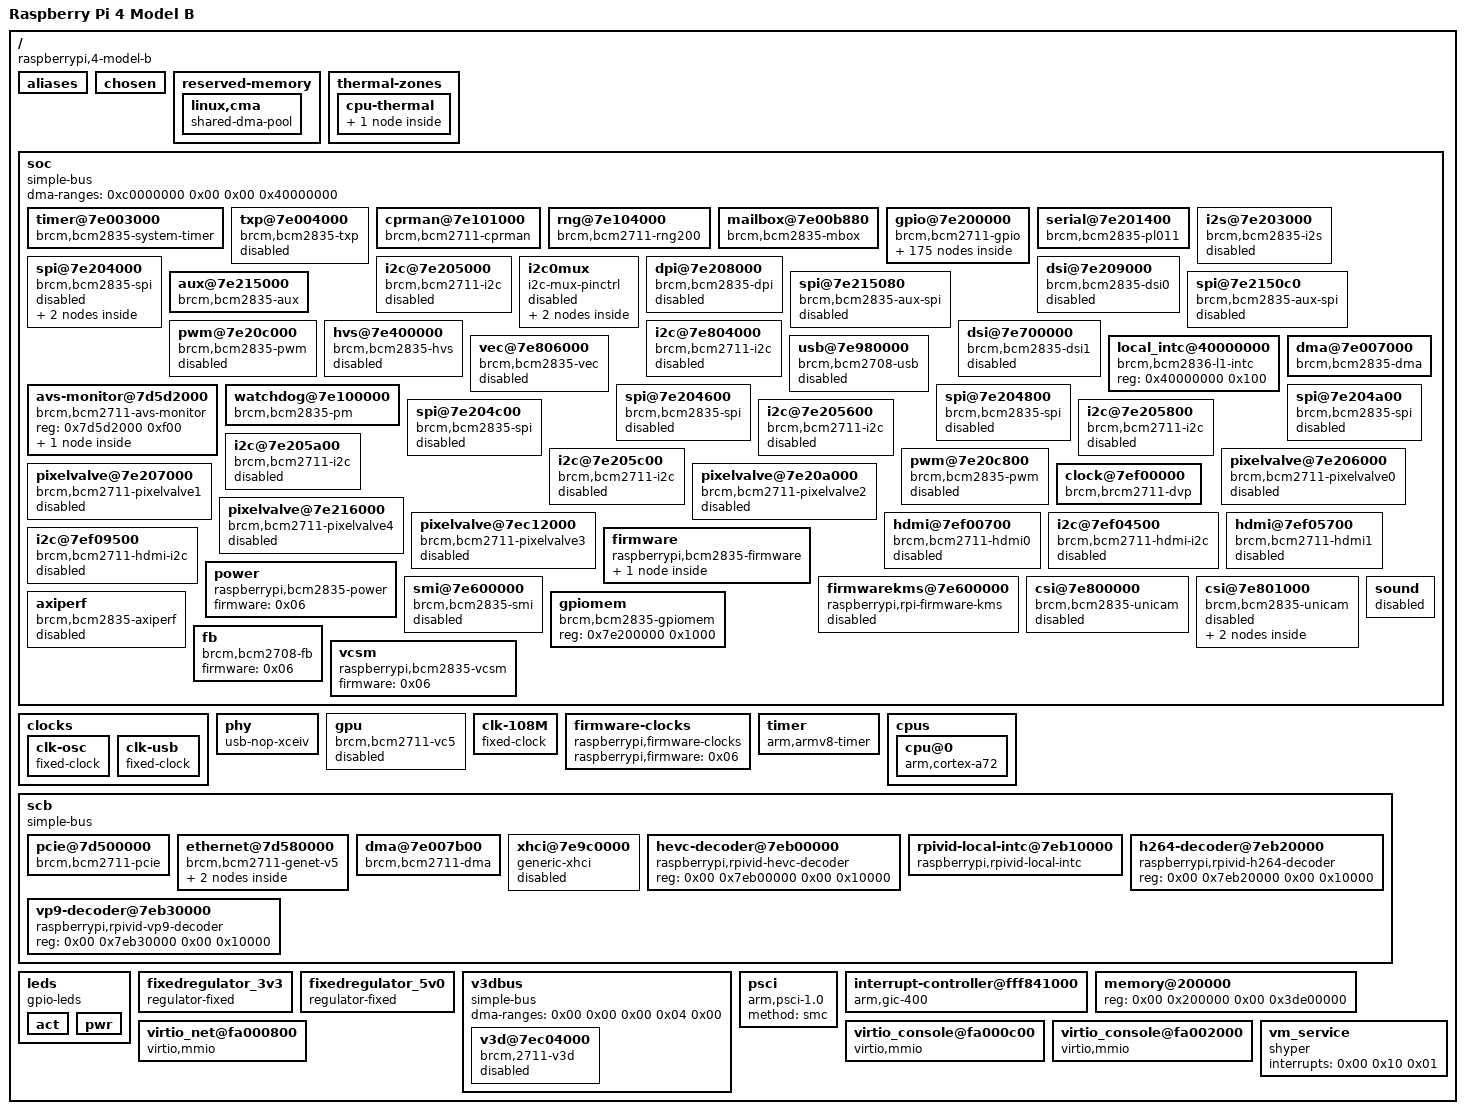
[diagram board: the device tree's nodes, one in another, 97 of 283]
/dts-v1/;

/memreserve/	0x0000000000000000 0x0000000000080000;
/ {
	compatible = "raspberrypi,4-model-b\0brcm,bcm2711";
	model = "Raspberry Pi 4 Model B";
	#address-cells = <0x02>;
	#size-cells = <0x02>;
	interrupt-parent = <0x01>;

	aliases {
		serial0 = "/soc/serial@7e201400";
		ethernet0 = "/scb/ethernet@7d580000";
		audio = "/soc/mailbox@7e00b840/bcm2835_audio";
		aux = "/soc/aux@7e215000";
		sound = "/soc/sound";
		soc = "/soc";
		dma = "/soc/dma@7e007000";
		watchdog = "/soc/watchdog@7e100000";
		random = "/soc/rng@7e104000";
		mailbox = "/soc/mailbox@7e00b880";
		gpio = "/soc/gpio@7e200000";
		i2s = "/soc/i2s@7e203000";
		i2c0 = "/soc/i2c0mux/i2c@0";
		i2c1 = "/soc/i2c@7e804000";
		i2c10 = "/soc/i2c0mux/i2c@1";
		spi0 = "/soc/spi@7e204000";
		spi1 = "/soc/spi@7e215080";
		spi2 = "/soc/spi@7e2150c0";
		usb = "/soc/usb@7e980000";
		leds = "/leds";
		fb = "/soc/fb";
		thermal = "/soc/avs-monitor@7d5d2000/thermal";
		axiperf = "/soc/axiperf";
		i2c3 = "/soc/i2c@7e205600";
		i2c4 = "/soc/i2c@7e205800";
		i2c5 = "/soc/i2c@7e205a00";
		i2c6 = "/soc/i2c@7e205c00";
		pcie0 = "/scb/pcie@7d500000";
	};

	chosen {
		// stdout-path = "serial0:115200n8";
		bootargs = "coherent_pool=1M snd_bcm2835.enable_compat_alsa=0 snd_bcm2835.enable_hdmi=1 snd_bcm2835.enable_headphones=1 console=ttyAMA0,115200n8 root=/dev/sda1 rootfstype=ext4 rw audit=0 rootwait default_hugepagesz=32M hugepagesz=32M hugepages=4";
		// bootargs = "console=ttyAMA0,115200n8 rdinit=/sbin/init audit=0";
		// linux,initrd-start = <0x18000000>;
        // linux,initrd-end = <0x1810dab1>;
	};

	reserved-memory {
		#address-cells = <0x02>;
		#size-cells = <0x01>;
		ranges;
		phandle = <0x3d>;

		linux,cma {
			compatible = "shared-dma-pool";
			size = <0x4000000>;
			reusable;
			linux,cma-default;
			alloc-ranges = <0x00 0x00 0x30000000>;
			phandle = <0x3e>;
		};
	};

	thermal-zones {

		cpu-thermal {
			polling-delay-passive = <0x00>;
			polling-delay = <0x3e8>;
			coefficients = <0xfffffe19 0x641b8>;
			thermal-sensors = <0x02>;
			phandle = <0x3f>;

			cooling-maps {
			};
		};
	};

	soc {
		compatible = "simple-bus";
		#address-cells = <0x01>;
		#size-cells = <0x01>;
		ranges = <0x7e000000 0x00 0xfe000000 0x1800000 0x7c000000 0x00 0xfc000000 0x2000000 0x40000000 0x00 0xff800000 0x800000>;
		dma-ranges = <0xc0000000 0x00 0x00 0x40000000>;
		phandle = <0x40>;

		timer@7e003000 {
			compatible = "brcm,bcm2835-system-timer";
			reg = <0x7e003000 0x1000>;
			interrupts = <0x00 0x40 0x04 0x00 0x41 0x04 0x00 0x42 0x04 0x00 0x43 0x04>;
			clock-frequency = <0xf4240>;
			phandle = <0x41>;
		};

		txp@7e004000 {
			compatible = "brcm,bcm2835-txp";
			reg = <0x7e004000 0x20>;
			interrupts = <0x00 0x4b 0x04>;
			status = "disabled";
			phandle = <0x42>;
		};

		cprman@7e101000 {
			compatible = "brcm,bcm2711-cprman";
			#clock-cells = <0x01>;
			reg = <0x7e101000 0x2000>;
			clocks = <0x03 0x04 0x00 0x04 0x01 0x04 0x02 0x05 0x00 0x05 0x01 0x05 0x02>;
			firmware = <0x06>;
			phandle = <0x07>;
		};

		rng@7e104000 {
			compatible = "brcm,bcm2711-rng200";
			reg = <0x7e104000 0x10>;
			interrupts = <0x00 0x7d 0x04>;
			status = "okay";
			phandle = <0x32>;
		};

		mailbox@7e00b880 {
			compatible = "brcm,bcm2835-mbox";
			reg = <0x7e00b880 0x40>;
			interrupts = <0x00 0x21 0x04>;
			#mbox-cells = <0x00>;
			phandle = <0x1f>;
		};

		gpio@7e200000 {
			compatible = "brcm,bcm2711-gpio\0brcm,bcm2835-gpio";
			reg = <0x7e200000 0xb4>;
			interrupts = <0x00 0x71 0x04 0x00 0x72 0x04>;
			gpio-controller;
			#gpio-cells = <0x02>;
			interrupt-controller;
			#interrupt-cells = <0x02>;
			pinctrl-names = "default";
			phandle = <0x0e>;

			dpi_gpio0 {
				brcm,pins = <0x00 0x01 0x02 0x03 0x04 0x05 0x06 0x07 0x08 0x09 0x0a 0x0b 0x0c 0x0d 0x0e 0x0f 0x10 0x11 0x12 0x13 0x14 0x15 0x16 0x17 0x18 0x19 0x1a 0x1b>;
				brcm,function = <0x06>;
				phandle = <0x43>;
			};

			emmc_gpio22 {
				brcm,pins = <0x16 0x17 0x18 0x19 0x1a 0x1b>;
				brcm,function = <0x07>;
				phandle = <0x44>;
			};

			emmc_gpio34 {
				brcm,pins = <0x22 0x23 0x24 0x25 0x26 0x27>;
				brcm,function = <0x07>;
				brcm,pull = <0x00 0x02 0x02 0x02 0x02 0x02>;
				phandle = <0x45>;
			};

			emmc_gpio48 {
				brcm,pins = <0x30 0x31 0x32 0x33 0x34 0x35>;
				brcm,function = <0x07>;
				phandle = <0x21>;
			};

			gpclk0_gpio4 {
				brcm,pins = <0x04>;
				brcm,function = <0x04>;
				phandle = <0x46>;
			};

			gpclk1_gpio5 {
				brcm,pins = <0x05>;
				brcm,function = <0x04>;
				phandle = <0x47>;
			};

			gpclk1_gpio42 {
				brcm,pins = <0x2a>;
				brcm,function = <0x04>;
				phandle = <0x48>;
			};

			gpclk1_gpio44 {
				brcm,pins = <0x2c>;
				brcm,function = <0x04>;
				phandle = <0x49>;
			};

			gpclk2_gpio6 {
				brcm,pins = <0x06>;
				brcm,function = <0x04>;
				phandle = <0x4a>;
			};

			gpclk2_gpio43 {
				brcm,pins = <0x2b>;
				brcm,function = <0x04>;
				brcm,pull = <0x00>;
				phandle = <0x4b>;
			};

			i2c0_gpio0 {
				brcm,pins = <0x00 0x01>;
				brcm,function = <0x04>;
				phandle = <0x10>;
			};

			i2c0_gpio28 {
				brcm,pins = <0x1c 0x1d>;
				brcm,function = <0x04>;
				phandle = <0x4c>;
			};

			i2c0_gpio44 {
				brcm,pins = <0x2c 0x2d>;
				brcm,function = <0x05>;
				phandle = <0x11>;
			};

			i2c1_gpio2 {
				brcm,pins = <0x02 0x03>;
				brcm,function = <0x04>;
				phandle = <0x4d>;
			};

			i2c1_gpio44 {
				brcm,pins = <0x2c 0x2d>;
				brcm,function = <0x06>;
				phandle = <0x4e>;
			};

			jtag_gpio22 {
				brcm,pins = <0x16 0x17 0x18 0x19 0x1a 0x1b>;
				brcm,function = <0x03>;
				phandle = <0x4f>;
			};

			pcm_gpio18 {
				brcm,pins = <0x12 0x13 0x14 0x15>;
				brcm,function = <0x04>;
				phandle = <0x50>;
			};

			pcm_gpio28 {
				brcm,pins = <0x1c 0x1d 0x1e 0x1f>;
				brcm,function = <0x06>;
				phandle = <0x51>;
			};

			sdhost_gpio48 {
				brcm,pins = <0x30 0x31 0x32 0x33 0x34 0x35>;
				brcm,function = <0x04>;
				phandle = <0x52>;
			};

			spi0_gpio7 {
				brcm,pins = <0x07 0x08 0x09 0x0a 0x0b>;
				brcm,function = <0x04>;
				phandle = <0x53>;
			};

			spi0_gpio35 {
				brcm,pins = <0x23 0x24 0x25 0x26 0x27>;
				brcm,function = <0x04>;
				phandle = <0x54>;
			};

			spi1_gpio16 {
				brcm,pins = <0x10 0x11 0x12 0x13 0x14 0x15>;
				brcm,function = <0x03>;
				phandle = <0x55>;
			};

			spi2_gpio40 {
				brcm,pins = <0x28 0x29 0x2a 0x2b 0x2c 0x2d>;
				brcm,function = <0x03>;
				phandle = <0x56>;
			};

			uart0_gpio14 {
				brcm,pins = <0x0e 0x0f>;
				brcm,function = <0x04>;
				phandle = <0x57>;
			};

			uart0_ctsrts_gpio16 {
				brcm,pins = <0x10 0x11>;
				brcm,function = <0x07>;
				phandle = <0x58>;
			};

			uart0_ctsrts_gpio30 {
				brcm,pins = <0x1e 0x1f>;
				brcm,function = <0x07>;
				brcm,pull = <0x02 0x00>;
				phandle = <0x59>;
			};

			uart0_gpio32 {
				brcm,pins = <0x20 0x21>;
				brcm,function = <0x07>;
				brcm,pull = <0x00 0x02>;
				phandle = <0x5a>;
			};

			uart0_gpio36 {
				brcm,pins = <0x24 0x25>;
				brcm,function = <0x06>;
				phandle = <0x5b>;
			};

			uart0_ctsrts_gpio38 {
				brcm,pins = <0x26 0x27>;
				brcm,function = <0x06>;
				phandle = <0x5c>;
			};

			uart1_gpio14 {
				brcm,pins = <0x0e 0x0f>;
				brcm,function = <0x02>;
				phandle = <0x5d>;
			};

			uart1_ctsrts_gpio16 {
				brcm,pins = <0x10 0x11>;
				brcm,function = <0x02>;
				phandle = <0x5e>;
			};

			uart1_gpio32 {
				brcm,pins = <0x20 0x21>;
				brcm,function = <0x02>;
				phandle = <0x5f>;
			};

			uart1_ctsrts_gpio30 {
				brcm,pins = <0x1e 0x1f>;
				brcm,function = <0x02>;
				phandle = <0x60>;
			};

			uart1_gpio40 {
				brcm,pins = <0x28 0x29>;
				brcm,function = <0x02>;
				phandle = <0x61>;
			};

			uart1_ctsrts_gpio42 {
				brcm,pins = <0x2a 0x2b>;
				brcm,function = <0x02>;
				phandle = <0x62>;
			};

			gpclk0_gpio49 {
				phandle = <0x63>;

				pin-gpclk {
					pins = "gpio49";
					function = "alt1";
					bias-disable;
				};
			};

			gpclk1_gpio50 {
				phandle = <0x64>;

				pin-gpclk {
					pins = "gpio50";
					function = "alt1";
					bias-disable;
				};
			};

			gpclk2_gpio51 {
				phandle = <0x65>;

				pin-gpclk {
					pins = "gpio51";
					function = "alt1";
					bias-disable;
				};
			};

			i2c0_gpio46 {
				phandle = <0x66>;

				pin-sda {
					function = "alt0";
					pins = "gpio46";
					bias-pull-up;
				};

				pin-scl {
					function = "alt0";
					pins = "gpio47";
					bias-disable;
				};
			};

			i2c1_gpio46 {
				phandle = <0x67>;

				pin-sda {
					function = "alt1";
					pins = "gpio46";
					bias-pull-up;
				};

				pin-scl {
					function = "alt1";
					pins = "gpio47";
					bias-disable;
				};
			};

			i2c3_gpio2 {
				phandle = <0x68>;

				pin-sda {
					function = "alt5";
					pins = "gpio2";
					bias-pull-up;
				};

				pin-scl {
					function = "alt5";
					pins = "gpio3";
					bias-disable;
				};
			};

			i2c3_gpio4 {
				phandle = <0x69>;

				pin-sda {
					function = "alt5";
					pins = "gpio4";
					bias-pull-up;
				};

				pin-scl {
					function = "alt5";
					pins = "gpio5";
					bias-disable;
				};
			};

			i2c4_gpio6 {
				phandle = <0x6a>;

				pin-sda {
					function = "alt5";
					pins = "gpio6";
					bias-pull-up;
				};

				pin-scl {
					function = "alt5";
					pins = "gpio7";
					bias-disable;
				};
			};

			i2c4_gpio8 {
				phandle = <0x6b>;

				pin-sda {
					function = "alt5";
					pins = "gpio8";
					bias-pull-up;
				};

				pin-scl {
					function = "alt5";
					pins = "gpio9";
					bias-disable;
				};
			};

			i2c5_gpio10 {
				phandle = <0x6c>;

				pin-sda {
					function = "alt5";
					pins = "gpio10";
					bias-pull-up;
				};

				pin-scl {
					function = "alt5";
					pins = "gpio11";
					bias-disable;
				};
			};

			i2c5_gpio12 {
				phandle = <0x6d>;

				pin-sda {
					function = "alt5";
					pins = "gpio12";
					bias-pull-up;
				};

				pin-scl {
					function = "alt5";
					pins = "gpio13";
					bias-disable;
				};
			};

			i2c6_gpio0 {
				phandle = <0x6e>;

				pin-sda {
					function = "alt5";
					pins = "gpio0";
					bias-pull-up;
				};

				pin-scl {
					function = "alt5";
					pins = "gpio1";
					bias-disable;
				};
			};

			i2c6_gpio22 {
				phandle = <0x6f>;

				pin-sda {
					function = "alt5";
					pins = "gpio22";
					bias-pull-up;
				};

				pin-scl {
					function = "alt5";
					pins = "gpio23";
					bias-disable;
				};
			};

			i2c_slave_gpio8 {
				phandle = <0x70>;

				pins-i2c-slave {
					pins = "gpio8\0gpio9\0gpio10\0gpio11";
					function = "alt3";
				};
			};

			jtag_gpio48 {
				phandle = <0x71>;

				pins-jtag {
					pins = "gpio48\0gpio49\0gpio50\0gpio51\0gpio52\0gpio53";
					function = "alt4";
				};
			};

			mii_gpio28 {
				phandle = <0x72>;

				pins-mii {
					pins = "gpio28\0gpio29\0gpio30\0gpio31";
					function = "alt4";
				};
			};

			mii_gpio36 {
				phandle = <0x73>;

				pins-mii {
					pins = "gpio36\0gpio37\0gpio38\0gpio39";
					function = "alt5";
				};
			};

			pcm_gpio50 {
				phandle = <0x74>;

				pins-pcm {
					pins = "gpio50\0gpio51\0gpio52\0gpio53";
					function = "alt2";
				};
			};

			pwm0_0_gpio12 {
				phandle = <0x75>;

				pin-pwm {
					pins = "gpio12";
					function = "alt0";
					bias-disable;
				};
			};

			pwm0_0_gpio18 {
				phandle = <0x76>;

				pin-pwm {
					pins = "gpio18";
					function = "alt5";
					bias-disable;
				};
			};

			pwm1_0_gpio40 {
				phandle = <0x19>;

				pin-pwm {
					pins = "gpio40";
					function = "alt0";
					bias-disable;
				};
			};

			pwm0_1_gpio13 {
				phandle = <0x77>;

				pin-pwm {
					pins = "gpio13";
					function = "alt0";
					bias-disable;
				};
			};

			pwm0_1_gpio19 {
				phandle = <0x78>;

				pin-pwm {
					pins = "gpio19";
					function = "alt5";
					bias-disable;
				};
			};

			pwm1_1_gpio41 {
				phandle = <0x1a>;

				pin-pwm {
					pins = "gpio41";
					function = "alt0";
					bias-disable;
				};
			};

			pwm0_1_gpio45 {
				phandle = <0x79>;

				pin-pwm {
					pins = "gpio45";
					function = "alt0";
					bias-disable;
				};
			};

			pwm0_0_gpio52 {
				phandle = <0x7a>;

				pin-pwm {
					pins = "gpio52";
					function = "alt1";
					bias-disable;
				};
			};

			pwm0_1_gpio53 {
				phandle = <0x7b>;

				pin-pwm {
					pins = "gpio53";
					function = "alt1";
					bias-disable;
				};
			};

			rgmii_gpio35 {
				phandle = <0x7c>;

				pin-start-stop {
					pins = "gpio35";
					function = "alt4";
				};

				pin-rx-ok {
					pins = "gpio36";
					function = "alt4";
				};
			};

			rgmii_irq_gpio34 {
				phandle = <0x7d>;

				pin-irq {
					pins = "gpio34";
					function = "alt5";
				};
			};

			rgmii_irq_gpio39 {
				phandle = <0x7e>;

				pin-irq {
					pins = "gpio39";
					function = "alt4";
				};
			};

			rgmii_mdio_gpio28 {
				phandle = <0x7f>;

				pins-mdio {
					pins = "gpio28\0gpio29";
					function = "alt5";
				};
			};

			rgmii_mdio_gpio37 {
				phandle = <0x80>;

				pins-mdio {
					pins = "gpio37\0gpio38";
					function = "alt4";
				};
			};

			spi0_gpio46 {
				phandle = <0x81>;

				pins-spi {
					pins = "gpio46\0gpio47\0gpio48\0gpio49";
					function = "alt2";
				};
			};

			spi2_gpio46 {
				phandle = <0x82>;

				pins-spi {
					pins = "gpio46\0gpio47\0gpio48\0gpio49\0gpio50";
					function = "alt5";
				};
			};

			spi3_gpio0 {
				phandle = <0x83>;

				pins-spi {
					pins = "gpio0\0gpio1\0gpio2\0gpio3";
					function = "alt3";
				};
			};

			spi4_gpio4 {
				phandle = <0x84>;

				pins-spi {
					pins = "gpio4\0gpio5\0gpio6\0gpio7";
					function = "alt3";
				};
			};

			spi5_gpio12 {
				phandle = <0x85>;

				pins-spi {
					pins = "gpio12\0gpio13\0gpio14\0gpio15";
					function = "alt3";
				};
			};

			spi6_gpio18 {
				phandle = <0x86>;

				pins-spi {
					pins = "gpio18\0gpio19\0gpio20\0gpio21";
					function = "alt3";
				};
			};

			uart2_gpio0 {
				phandle = <0x87>;

				pin-tx {
					pins = "gpio0";
					function = "alt4";
					bias-disable;
				};

				pin-rx {
					pins = "gpio1";
					function = "alt4";
					bias-pull-up;
				};
			};

			uart2_ctsrts_gpio2 {
				phandle = <0x88>;

				pin-cts {
					pins = "gpio2";
					function = "alt4";
					bias-pull-up;
				};

				pin-rts {
					pins = "gpio3";
					function = "alt4";
					bias-disable;
				};
			};

			uart3_gpio4 {
				phandle = <0x89>;

				pin-tx {
					pins = "gpio4";
					function = "alt4";
					bias-disable;
				};

				pin-rx {
					pins = "gpio5";
					function = "alt4";
					bias-pull-up;
				};
			};

			uart3_ctsrts_gpio6 {
				phandle = <0x8a>;

				pin-cts {
					pins = "gpio6";
					function = "alt4";
					bias-pull-up;
				};

				pin-rts {
					pins = "gpio7";
					function = "alt4";
					bias-disable;
				};
			};

			uart4_gpio8 {
				phandle = <0x8b>;

				pin-tx {
					pins = "gpio8";
					function = "alt4";
					bias-disable;
				};

				pin-rx {
					pins = "gpio9";
					function = "alt4";
					bias-pull-up;
				};
			};

			uart4_ctsrts_gpio10 {
				phandle = <0x8c>;

				pin-cts {
					pins = "gpio10";
					function = "alt4";
					bias-pull-up;
				};

				pin-rts {
					pins = "gpio11";
					function = "alt4";
					bias-disable;
				};
			};

			uart5_gpio12 {
				phandle = <0x8d>;

				pin-tx {
					pins = "gpio12";
					function = "alt4";
					bias-disable;
				};

				pin-rx {
					pins = "gpio13";
					function = "alt4";
					bias-pull-up;
				};
			};

			uart5_ctsrts_gpio14 {
				phandle = <0x8e>;

				pin-cts {
					pins = "gpio14";
					function = "alt4";
					bias-pull-up;
				};

				pin-rts {
					pins = "gpio15";
					function = "alt4";
					bias-disable;
				};
			};

			gpioout {
				brcm,pins = <0x06>;
				brcm,function = <0x01>;
				phandle = <0x8f>;
			};

			alt0 {
				brcm,pins = <0x04 0x05 0x07 0x08 0x09 0x0a 0x0b>;
				brcm,function = <0x04>;
				phandle = <0x90>;
			};

			dpi_18bit_gpio0 {
				brcm,pins = <0x00 0x01 0x02 0x03 0x04 0x05 0x06 0x07 0x08 0x09 0x0a 0x0b 0x0c 0x0d 0x0e 0x0f 0x10 0x11 0x12 0x13 0x14 0x15>;
				brcm,function = <0x06>;
				phandle = <0x91>;
			};

			spi0_pins {
				brcm,pins = <0x09 0x0a 0x0b>;
				brcm,function = <0x04>;
				phandle = <0x0c>;
			};

			spi0_cs_pins {
				brcm,pins = <0x08 0x07>;
				brcm,function = <0x01>;
				phandle = <0x0d>;
			};

			spi3_pins {
				brcm,pins = <0x01 0x02 0x03>;
				brcm,function = <0x07>;
				phandle = <0x92>;
			};

			spi3_cs_pins {
				brcm,pins = <0x00 0x18>;
				brcm,function = <0x01>;
				phandle = <0x93>;
			};

			spi4_pins {
				brcm,pins = <0x05 0x06 0x07>;
				brcm,function = <0x07>;
				phandle = <0x94>;
			};

			spi4_cs_pins {
				brcm,pins = <0x04 0x19>;
				brcm,function = <0x01>;
				phandle = <0x95>;
			};

			spi5_pins {
				brcm,pins = <0x0d 0x0e 0x0f>;
				brcm,function = <0x07>;
				phandle = <0x96>;
			};

			spi5_cs_pins {
				brcm,pins = <0x0c 0x1a>;
				brcm,function = <0x01>;
				phandle = <0x97>;
			};

			spi6_pins {
				brcm,pins = <0x13 0x14 0x15>;
				brcm,function = <0x07>;
				phandle = <0x98>;
			};

			spi6_cs_pins {
				brcm,pins = <0x12 0x1b>;
				brcm,function = <0x01>;
				phandle = <0x99>;
			};

			i2c0 {
				brcm,pins = <0x00 0x01>;
				brcm,function = <0x04>;
				brcm,pull = <0x02>;
				phandle = <0x9a>;
			};

			i2c1 {
				brcm,pins = <0x02 0x03>;
				brcm,function = <0x04>;
				brcm,pull = <0x02>;
				phandle = <0x16>;
			};

			i2c3 {
				brcm,pins = <0x04 0x05>;
				brcm,function = <0x02>;
				brcm,pull = <0x02>;
				phandle = <0x9b>;
			};

			i2c4 {
				brcm,pins = <0x08 0x09>;
				brcm,function = <0x02>;
				brcm,pull = <0x02>;
				phandle = <0x9c>;
			};

			i2c5 {
				brcm,pins = <0x0c 0x0d>;
				brcm,function = <0x02>;
				brcm,pull = <0x02>;
				phandle = <0x9d>;
			};

			i2c6 {
				brcm,pins = <0x16 0x17>;
				brcm,function = <0x02>;
				brcm,pull = <0x02>;
				phandle = <0x9e>;
			};

			i2s {
				brcm,pins = <0x12 0x13 0x14 0x15>;
				brcm,function = <0x04>;
				phandle = <0x0b>;
			};

			sdio_pins {
				brcm,pins = <0x22 0x23 0x24 0x25 0x26 0x27>;
				brcm,function = <0x07>;
				brcm,pull = <0x00 0x02 0x02 0x02 0x02 0x02>;
				phandle = <0x22>;
			};

			bt_pins {
				brcm,pins = "-";
				brcm,function = <0x00>;
				brcm,pull = <0x02>;
				phandle = <0x09>;
			};

			uart0_pins {
				brcm,pins = <0x20 0x21>;
				brcm,function = <0x07>;
				brcm,pull = <0x00 0x02>;
				phandle = <0x08>;
			};

			uart1_pins {
				brcm,pins;
				brcm,function;
				brcm,pull;
				phandle = <0x14>;
			};

			uart2_pins {
				brcm,pins = <0x00 0x01>;
				brcm,function = <0x03>;
				brcm,pull = <0x00 0x02>;
				phandle = <0x9f>;
			};

			uart3_pins {
				brcm,pins = <0x04 0x05>;
				brcm,function = <0x03>;
				brcm,pull = <0x00 0x02>;
				phandle = <0xa0>;
			};

			uart4_pins {
				brcm,pins = <0x08 0x09>;
				brcm,function = <0x03>;
				brcm,pull = <0x00 0x02>;
				phandle = <0xa1>;
			};

			uart5_pins {
				brcm,pins = <0x0c 0x0d>;
				brcm,function = <0x03>;
				brcm,pull = <0x00 0x02>;
				phandle = <0xa2>;
			};

			audio_pins {
				brcm,pins = <0x28 0x29>;
				brcm,function = <0x04>;
				phandle = <0x20>;
			};
		};

		serial@7e201400 {
			compatible = "brcm,bcm2835-pl011\0arm,pl011\0arm,primecell";
			reg = <0x7e201400 0x200>;
			interrupts = <0x00 0x79 0x04>;
			clocks = <0x07 0x13 0x07 0x14>;
			clock-names = "uartclk\0apb_pclk";
			arm,primecell-periphid = <0x241011>;
			uart-has-rtscts;
			status = "okay";
			cts-event-workaround;
			phandle = <0x2a>;
		};

		i2s@7e203000 {
			compatible = "brcm,bcm2835-i2s";
			reg = <0x7e203000 0x24>;
			clocks = <0x07 0x1f>;
			status = "disabled";
			#sound-dai-cells = <0x00>;
			dmas = <0x0a 0x02 0x0a 0x03>;
			dma-names = "tx\0rx";
			pinctrl-names = "default";
			pinctrl-0 = <0x0b>;
			phandle = <0x2c>;
		};

		spi@7e204000 {
			compatible = "brcm,bcm2835-spi";
			reg = <0x7e204000 0x200>;
			interrupts = <0x00 0x76 0x04>;
			clocks = <0x07 0x14>;
			#address-cells = <0x01>;
			#size-cells = <0x00>;
			status = "disabled";
			dmas = <0x0a 0x06 0x0a 0x07>;
			dma-names = "tx\0rx";
			pinctrl-names = "default";
			pinctrl-0 = <0x0c 0x0d>;
			cs-gpios = <0x0e 0x08 0x01 0x0e 0x07 0x01>;
			phandle = <0x2d>;

			spidev@0 {
				compatible = "spidev";
				reg = <0x00>;
				#address-cells = <0x01>;
				#size-cells = <0x00>;
				spi-max-frequency = <0x7735940>;
				phandle = <0xa3>;
			};

			spidev@1 {
				compatible = "spidev";
				reg = <0x01>;
				#address-cells = <0x01>;
				#size-cells = <0x00>;
				spi-max-frequency = <0x7735940>;
				phandle = <0xa4>;
			};
		};

		i2c@7e205000 {
			compatible = "brcm,bcm2711-i2c\0brcm,bcm2835-i2c";
			reg = <0x7e205000 0x200>;
			interrupts = <0x00 0x75 0x04>;
			clocks = <0x07 0x14>;
			#address-cells = <0x01>;
			#size-cells = <0x00>;
			status = "disabled";
			clock-frequency = <0x186a0>;
			phandle = <0x0f>;
		};

		i2c0mux {
			compatible = "i2c-mux-pinctrl";
			#address-cells = <0x01>;
			#size-cells = <0x00>;
			i2c-parent = <0x0f>;
			pinctrl-names = "i2c0\0i2c_csi_dsi";
			status = "disabled";
			pinctrl-0 = <0x10>;
			pinctrl-1 = <0x11>;
			phandle = <0x2e>;

			i2c@0 {
				reg = <0x00>;
				#address-cells = <0x01>;
				#size-cells = <0x00>;
				phandle = <0xa5>;
			};

			i2c@1 {
				reg = <0x01>;
				#address-cells = <0x01>;
				#size-cells = <0x00>;
				phandle = <0xa6>;
			};
		};

		dpi@7e208000 {
			compatible = "brcm,bcm2835-dpi";
			reg = <0x7e208000 0x8c>;
			clocks = <0x07 0x14 0x07 0x2c>;
			clock-names = "core\0pixel";
			#address-cells = <0x01>;
			#size-cells = <0x00>;
			status = "disabled";
			phandle = <0xa7>;
		};

		dsi@7e209000 {
			compatible = "brcm,bcm2835-dsi0";
			reg = <0x7e209000 0x78>;
			interrupts = <0x00 0x64 0x04>;
			#address-cells = <0x01>;
			#size-cells = <0x00>;
			#clock-cells = <0x01>;
			clocks = <0x07 0x20 0x07 0x2f 0x07 0x31>;
			clock-names = "phy\0escape\0pixel";
			clock-output-names = "dsi0_byte\0dsi0_ddr2\0dsi0_ddr";
			status = "disabled";
			power-domains = <0x12 0x11>;
			phandle = <0x04>;
		};

		aux@7e215000 {
			compatible = "brcm,bcm2835-aux";
			#clock-cells = <0x01>;
			reg = <0x7e215000 0x08>;
			clocks = <0x07 0x14>;
			phandle = <0x13>;
		};

		spi@7e215080 {
			compatible = "brcm,bcm2835-aux-spi";
			reg = <0x7e215080 0x40>;
			interrupts = <0x00 0x5d 0x04>;
			clocks = <0x13 0x01>;
			#address-cells = <0x01>;
			#size-cells = <0x00>;
			status = "disabled";
			phandle = <0xa8>;
		};

		spi@7e2150c0 {
			compatible = "brcm,bcm2835-aux-spi";
			reg = <0x7e2150c0 0x40>;
			interrupts = <0x00 0x5d 0x04>;
			clocks = <0x13 0x02>;
			#address-cells = <0x01>;
			#size-cells = <0x00>;
			status = "disabled";
			phandle = <0xa9>;
		};

		pwm@7e20c000 {
			compatible = "brcm,bcm2835-pwm";
			reg = <0x7e20c000 0x28>;
			clocks = <0x07 0x1e>;
			assigned-clocks = <0x07 0x1e>;
			assigned-clock-rates = <0x989680>;
			#pwm-cells = <0x02>;
			status = "disabled";
			phandle = <0xaa>;
		};

		hvs@7e400000 {
			compatible = "brcm,bcm2835-hvs";
			reg = <0x7e400000 0x6000>;
			interrupts = <0x00 0x61 0x04>;
			clocks = <0x15 0x04>;
			status = "disabled";
			phandle = <0xab>;
		};

		dsi@7e700000 {
			compatible = "brcm,bcm2835-dsi1";
			reg = <0x7e700000 0x8c>;
			interrupts = <0x00 0x6c 0x04>;
			#address-cells = <0x01>;
			#size-cells = <0x00>;
			#clock-cells = <0x01>;
			clocks = <0x07 0x23 0x07 0x30 0x07 0x32>;
			clock-names = "phy\0escape\0pixel";
			clock-output-names = "dsi1_byte\0dsi1_ddr2\0dsi1_ddr";
			status = "disabled";
			power-domains = <0x12 0x12>;
			phandle = <0x05>;
		};

		i2c@7e804000 {
			compatible = "brcm,bcm2711-i2c\0brcm,bcm2835-i2c";
			reg = <0x7e804000 0x1000>;
			interrupts = <0x00 0x75 0x04>;
			clocks = <0x07 0x14>;
			#address-cells = <0x01>;
			#size-cells = <0x00>;
			status = "disabled";
			pinctrl-names = "default";
			pinctrl-0 = <0x16>;
			clock-frequency = <0x186a0>;
			phandle = <0x2f>;
		};

		vec@7e806000 {
			compatible = "brcm,bcm2835-vec";
			reg = <0x7e806000 0x1000>;
			clocks = <0x07 0x18>;
			interrupts = <0x00 0x7b 0x04>;
			status = "disabled";
			power-domains = <0x12 0x07>;
			phandle = <0xac>;
		};

		usb@7e980000 {
			compatible = "brcm,bcm2708-usb";
			reg = <0x7e980000 0x10000 0x7e00b200 0x200>;
			interrupts = <0x00 0x49 0x04 0x00 0x28 0x04>;
			#address-cells = <0x01>;
			#size-cells = <0x00>;
			clocks = <0x17>;
			clock-names = "otg";
			phys = <0x18>;
			phy-names = "usb2-phy";
			power-domains = <0x12 0x06>;
			interrupt-names = "usb\0soft";
			status = "disabled";
			phandle = <0xad>;
		};

		local_intc@40000000 {
			compatible = "brcm,bcm2836-l1-intc";
			reg = <0x40000000 0x100>;
			phandle = <0xae>;
		};

		avs-monitor@7d5d2000 {
			compatible = "brcm,bcm2711-avs-monitor\0syscon\0simple-mfd";
			reg = <0x7d5d2000 0xf00>;
			phandle = <0xaf>;

			thermal {
				compatible = "brcm,bcm2711-thermal";
				#thermal-sensor-cells = <0x00>;
				phandle = <0x02>;
			};
		};

		dma@7e007000 {
			compatible = "brcm,bcm2835-dma";
			reg = <0x7e007000 0xb00>;
			interrupts = <0x00 0x50 0x04 0x00 0x51 0x04 0x00 0x52 0x04 0x00 0x53 0x04 0x00 0x54 0x04 0x00 0x55 0x04 0x00 0x56 0x04 0x00 0x57 0x04 0x00 0x57 0x04 0x00 0x58 0x04 0x00 0x58 0x04>;
			interrupt-names = "dma0\0dma1\0dma2\0dma3\0dma4\0dma5\0dma6\0dma7\0dma8\0dma9\0dma10";
			#dma-cells = <0x01>;
			brcm,dma-channel-mask = <0x1f5>;
			phandle = <0x0a>;
		};

		watchdog@7e100000 {
			compatible = "brcm,bcm2835-pm\0brcm,bcm2835-pm-wdt";
			#power-domain-cells = <0x01>;
			#reset-cells = <0x01>;
			reg = <0x7e100000 0x114 0x7e00a000 0x24 0x7ec11000 0x20>;
			clocks = <0x07 0x15 0x07 0x1d 0x07 0x17 0x07 0x16>;
			clock-names = "v3d\0peri_image\0h264\0isp";
			system-power-controller;
			phandle = <0x31>;
		};

		spi@7e204600 {
			compatible = "brcm,bcm2835-spi";
			reg = <0x7e204600 0x200>;
			interrupts = <0x00 0x76 0x04>;
			clocks = <0x07 0x14>;
			#address-cells = <0x01>;
			#size-cells = <0x00>;
			status = "disabled";
			phandle = <0xb4>;
		};

		spi@7e204800 {
			compatible = "brcm,bcm2835-spi";
			reg = <0x7e204800 0x200>;
			interrupts = <0x00 0x76 0x04>;
			clocks = <0x07 0x14>;
			#address-cells = <0x01>;
			#size-cells = <0x00>;
			status = "disabled";
			phandle = <0xb5>;
		};

		spi@7e204a00 {
			compatible = "brcm,bcm2835-spi";
			reg = <0x7e204a00 0x200>;
			interrupts = <0x00 0x76 0x04>;
			clocks = <0x07 0x14>;
			#address-cells = <0x01>;
			#size-cells = <0x00>;
			status = "disabled";
			phandle = <0xb6>;
		};

		spi@7e204c00 {
			compatible = "brcm,bcm2835-spi";
			reg = <0x7e204c00 0x200>;
			interrupts = <0x00 0x76 0x04>;
			clocks = <0x07 0x14>;
			#address-cells = <0x01>;
			#size-cells = <0x00>;
			status = "disabled";
			phandle = <0xb7>;
		};

		i2c@7e205600 {
			compatible = "brcm,bcm2711-i2c\0brcm,bcm2835-i2c";
			reg = <0x7e205600 0x200>;
			interrupts = <0x00 0x75 0x04>;
			clocks = <0x07 0x14>;
			#address-cells = <0x01>;
			#size-cells = <0x00>;
			status = "disabled";
			phandle = <0xb8>;
		};

		i2c@7e205800 {
			compatible = "brcm,bcm2711-i2c\0brcm,bcm2835-i2c";
			reg = <0x7e205800 0x200>;
			interrupts = <0x00 0x75 0x04>;
			clocks = <0x07 0x14>;
			#address-cells = <0x01>;
			#size-cells = <0x00>;
			status = "disabled";
			phandle = <0xb9>;
		};

		i2c@7e205a00 {
			compatible = "brcm,bcm2711-i2c\0brcm,bcm2835-i2c";
			reg = <0x7e205a00 0x200>;
			interrupts = <0x00 0x75 0x04>;
			clocks = <0x07 0x14>;
			#address-cells = <0x01>;
			#size-cells = <0x00>;
			status = "disabled";
			phandle = <0xba>;
		};

		i2c@7e205c00 {
			compatible = "brcm,bcm2711-i2c\0brcm,bcm2835-i2c";
			reg = <0x7e205c00 0x200>;
			interrupts = <0x00 0x75 0x04>;
			clocks = <0x07 0x14>;
			#address-cells = <0x01>;
			#size-cells = <0x00>;
			status = "disabled";
			phandle = <0xbb>;
		};

		pixelvalve@7e206000 {
			compatible = "brcm,bcm2711-pixelvalve0";
			reg = <0x7e206000 0x100>;
			interrupts = <0x00 0x6d 0x04>;
			status = "disabled";
			phandle = <0xbc>;
		};

		pixelvalve@7e207000 {
			compatible = "brcm,bcm2711-pixelvalve1";
			reg = <0x7e207000 0x100>;
			interrupts = <0x00 0x6e 0x04>;
			status = "disabled";
			phandle = <0xbd>;
		};

		pixelvalve@7e20a000 {
			compatible = "brcm,bcm2711-pixelvalve2";
			reg = <0x7e20a000 0x100>;
			interrupts = <0x00 0x65 0x04>;
			status = "disabled";
			phandle = <0xbe>;
		};

		pwm@7e20c800 {
			compatible = "brcm,bcm2835-pwm";
			reg = <0x7e20c800 0x28>;
			clocks = <0x07 0x1e>;
			assigned-clocks = <0x07 0x1e>;
			assigned-clock-rates = <0x989680>;
			#pwm-cells = <0x02>;
			status = "disabled";
			pinctrl-names = "default";
			pinctrl-0 = <0x19 0x1a>;
			phandle = <0xbf>;
		};

		pixelvalve@7e216000 {
			compatible = "brcm,bcm2711-pixelvalve4";
			reg = <0x7e216000 0x100>;
			interrupts = <0x00 0x6e 0x04>;
			status = "disabled";
			phandle = <0xc0>;
		};

		pixelvalve@7ec12000 {
			compatible = "brcm,bcm2711-pixelvalve3";
			reg = <0x7ec12000 0x100>;
			interrupts = <0x00 0x6a 0x04>;
			status = "disabled";
			phandle = <0xc1>;
		};

		clock@7ef00000 {
			compatible = "brcm,brcm2711-dvp";
			reg = <0x7ef00000 0x10>;
			clocks = <0x1b>;
			#clock-cells = <0x01>;
			#reset-cells = <0x01>;
			phandle = <0x1c>;
		};

		hdmi@7ef00700 {
			compatible = "brcm,bcm2711-hdmi0";
			reg = <0x7ef00700 0x300 0x7ef00300 0x200 0x7ef00f00 0x80 0x7ef00f80 0x80 0x7ef01b00 0x200 0x7ef01f00 0x400 0x7ef00200 0x80 0x7ef04300 0x100 0x7ef20000 0x100 0x7ef00100 0x30>;
			reg-names = "hdmi\0dvp\0phy\0rm\0packet\0metadata\0csc\0cec\0hd\0intr2";
			clocks = <0x15 0x0d>;
			clock-names = "hdmi";
			resets = <0x1c 0x00>;
			ddc = <0x1d>;
			dmas = <0x0a 0x0a>;
			dma-names = "audio-rx";
			interrupts = <0x00 0x60 0x04>;
			status = "disabled";
			phandle = <0xc2>;
		};

		i2c@7ef04500 {
			compatible = "brcm,bcm2711-hdmi-i2c";
			reg = <0x7ef04500 0x100 0x7ef00b00 0x300>;
			reg-names = "bsc\0auto-i2c";
			clock-frequency = <0x17cdc>;
			status = "disabled";
			phandle = <0x1d>;
		};

		hdmi@7ef05700 {
			compatible = "brcm,bcm2711-hdmi1";
			reg = <0x7ef05700 0x300 0x7ef05300 0x200 0x7ef05f00 0x80 0x7ef05f80 0x80 0x7ef06b00 0x200 0x7ef06f00 0x400 0x7ef00280 0x80 0x7ef09300 0x100 0x7ef20000 0x100 0x7ef00100 0x30>;
			reg-names = "hdmi\0dvp\0phy\0rm\0packet\0metadata\0csc\0cec\0hd\0intr2";
			ddc = <0x1e>;
			clocks = <0x15 0x0d>;
			clock-names = "hdmi";
			resets = <0x1c 0x01>;
			dmas = <0x0a 0x11>;
			dma-names = "audio-rx";
			interrupts = <0x00 0x60 0x04>;
			status = "disabled";
			phandle = <0xc3>;
		};

		i2c@7ef09500 {
			compatible = "brcm,bcm2711-hdmi-i2c";
			reg = <0x7ef09500 0x100 0x7ef05b00 0x300>;
			reg-names = "bsc\0auto-i2c";
			clock-frequency = <0x17cdc>;
			status = "disabled";
			phandle = <0x1e>;
		};

		firmware {
			compatible = "raspberrypi,bcm2835-firmware\0simple-bus";
			mboxes = <0x1f>;
			dma-ranges;
			phandle = <0x06>;

			gpio {
				compatible = "raspberrypi,firmware-gpio";
				gpio-controller;
				#gpio-cells = <0x02>;
				gpio-line-names = "BT_ON\0WL_ON\0PWR_LED_OFF\0GLOBAL_RESET\0VDD_SD_IO_SEL\0CAM_GPIO\0SD_PWR_ON\0SD_OC_N";
				status = "okay";
				phandle = <0x29>;
			};
		};

		power {
			compatible = "raspberrypi,bcm2835-power";
			firmware = <0x06>;
			#power-domain-cells = <0x01>;
			phandle = <0x12>;
		};

		firmwarekms@7e600000 {
			compatible = "raspberrypi,rpi-firmware-kms";
			reg = <0x7e600000 0x100>;
			interrupts = <0x00 0x70 0x04>;
			brcm,firmware = <0x06>;
			status = "disabled";
			phandle = <0xc5>;
		};

		smi@7e600000 {
			compatible = "brcm,bcm2835-smi";
			reg = <0x7e600000 0x100>;
			interrupts = <0x00 0x70 0x04>;
			clocks = <0x07 0x2a>;
			assigned-clocks = <0x07 0x2a>;
			assigned-clock-rates = <0x7735940>;
			dmas = <0x0a 0x04>;
			dma-names = "rx-tx";
			status = "disabled";
			phandle = <0xc6>;
		};

		csi@7e800000 {
			compatible = "brcm,bcm2835-unicam";
			reg = <0x7e800000 0x800 0x7e802000 0x04>;
			interrupts = <0x00 0x66 0x04>;
			clocks = <0x07 0x2d>;
			clock-names = "lp";
			power-domains = <0x12 0x0c>;
			#address-cells = <0x01>;
			#size-cells = <0x00>;
			#clock-cells = <0x01>;
			status = "disabled";
			phandle = <0xc7>;
		};

		csi@7e801000 {
			compatible = "brcm,bcm2835-unicam";
			reg = <0x7e801000 0x800 0x7e802004 0x04>;
			interrupts = <0x00 0x67 0x04>;
			clocks = <0x07 0x2e>;
			clock-names = "lp";
			power-domains = <0x12 0x0d>;
			#address-cells = <0x01>;
			#size-cells = <0x00>;
			#clock-cells = <0x01>;
			status = "disabled";
			phandle = <0xc8>;

			port {

				endpoint {
					data-lanes = <0x01 0x02>;
				};
			};
		};

		axiperf {
			compatible = "brcm,bcm2835-axiperf";
			reg = <0x7e009800 0x100 0x7ee08000 0x100>;
			firmware = <0x06>;
			status = "disabled";
			phandle = <0x36>;
		};

		gpiomem {
			compatible = "brcm,bcm2835-gpiomem";
			reg = <0x7e200000 0x1000>;
		};

		fb {
			compatible = "brcm,bcm2708-fb";
			firmware = <0x06>;
			status = "okay";
			phandle = <0xc9>;
		};

		vcsm {
			compatible = "raspberrypi,bcm2835-vcsm";
			firmware = <0x06>;
			status = "okay";
			phandle = <0xca>;
		};

		sound {
			status = "disabled";
			phandle = <0xcb>;
		};
	};

	clocks {

		clk-osc {
			compatible = "fixed-clock";
			#clock-cells = <0x00>;
			clock-output-names = "osc";
			clock-frequency = <0x337f980>;
			phandle = <0x03>;
		};

		clk-usb {
			compatible = "fixed-clock";
			#clock-cells = <0x00>;
			clock-output-names = "otg";
			clock-frequency = <0x1c9c3800>;
			phandle = <0x17>;
		};
	};

	phy {
		compatible = "usb-nop-xceiv";
		#phy-cells = <0x00>;
		phandle = <0x18>;
	};

	gpu {
		compatible = "brcm,bcm2711-vc5";
		status = "disabled";
		phandle = <0xcc>;
	};

	clk-108M {
		#clock-cells = <0x00>;
		compatible = "fixed-clock";
		clock-frequency = <0x66ff300>;
		clock-output-names = "108MHz-clock";
		phandle = <0x1b>;
	};

	firmware-clocks {
		compatible = "raspberrypi,firmware-clocks";
		raspberrypi,firmware = <0x06>;
		#clock-cells = <0x01>;
		phandle = <0x15>;
	};

	timer {
		compatible = "arm,armv8-timer";
		interrupts = <0x01 0x0d 0xf08 0x01 0x0e 0xf08 0x01 0x0b 0xf08 0x01 0x0a 0xf08>;
		arm,cpu-registers-not-fw-configured;
	};

	cpus {
		#address-cells = <0x01>;
		#size-cells = <0x00>;

		cpu@0 {
			reg = <0x00>;
			compatible = "arm,cortex-a72";
			device_type = "cpu";
			enable-method = "psci";
			phandle = <0x23>;
		};

		// cpu@1 {
		// 	reg = <0x01>// ;
		// 	compatible = "arm,cortex-a72";
		// 	device_type = "cpu";
		// 	enable-method = "psci";
		// 	phandle = <0x24>;
		// };

		// cpu@2 {
		// 	reg = <0x02>;
		// 	compatible = "arm,cortex-a72";
		//	device_type = "cpu";
		//	enable-method = "psci";
		//	phandle = <0x25>;
		//};

		//cpu@3 {
		//	reg = <0x03>;
		//	compatible = "arm,cortex-a72";
		//	device_type = "cpu";
		//	enable-method = "psci";
		//	phandle = <0x26>;
		//};
	};

	scb {
		compatible = "simple-bus";
		#address-cells = <0x02>;
		#size-cells = <0x02>;
		ranges = <0x00 0x7c000000 0x00 0xfc000000 0x00 0x3800000 0x00 0x40000000 0x00 0xff800000 0x00 0x800000 0x06 0x00 0x06 0x00 0x00 0x40000000 0x00 0x00 0x00 0x00 0x00 0xfc000000>;
		dma-ranges = <0x00 0x00 0x00 0x00 0x00 0xfc000000 0x01 0x00 0x01 0x00 0x01 0x00>;
		phandle = <0xce>;

		pcie@7d500000 {
			compatible = "brcm,bcm2711-pcie";
			reg = <0x00 0x7d500000 0x00 0x9310>;
			device_type = "pci";
			#address-cells = <0x03>;
			#interrupt-cells = <0x01>;
			#size-cells = <0x02>;
			interrupts = <0x00 0x94 0x04 0x00 0x94 0x04>;
			interrupt-names = "pcie\0msi";
			interrupt-map-mask = <0x00 0x00 0x00 0x07>;
			interrupt-map = <0x00 0x00 0x00 0x01 0x01 0x00 0x8f 0x04>;
			msi-controller;
			msi-parent = <0x27>;
			ranges = <0x2000000 0x00 0xf8000000 0x06 0x00 0x00 0x4000000>;
			dma-ranges = <0x2000000 0x00 0x00 0x00 0x00 0x00 0xc0000000>;
			brcm,enable-ssc;
			phandle = <0x27>;
		};

		ethernet@7d580000 {
			compatible = "brcm,bcm2711-genet-v5\0brcm,genet-v5";
			reg = <0x00 0x7d580000 0x00 0x10000>;
			#address-cells = <0x01>;
			#size-cells = <0x01>;
			interrupts = <0x00 0x9d 0x04 0x00 0x9e 0x04>;
			status = "okay";
			phy-handle = <0x28>;
			phy-mode = "rgmii-rxid";
			phandle = <0xcf>;
			local-mac-address = [dc a6 32 74 0a 64];

			mdio@e14 {
				compatible = "brcm,genet-mdio-v5";
				reg = <0xe14 0x08>;
				reg-names = "mdio";
				#address-cells = <0x00>;
				#size-cells = <0x01>;
				phandle = <0xd0>;

				ethernet-phy@1 {
					reg = <0x01>;
					led-modes = <0x00 0x08>;
					phandle = <0x28>;
				};
			};
		};

		dma@7e007b00 {
			compatible = "brcm,bcm2711-dma";
			reg = <0x00 0x7e007b00 0x00 0x400>;
			interrupts = <0x00 0x59 0x04 0x00 0x5a 0x04 0x00 0x5b 0x04 0x00 0x5c 0x04>;
			interrupt-names = "dma11\0dma12\0dma13\0dma14";
			#dma-cells = <0x01>;
			brcm,dma-channel-mask = <0x7000>;
			phandle = <0x3a>;
		};

		xhci@7e9c0000 {
			compatible = "generic-xhci";
			status = "disabled";
			reg = <0x00 0x7e9c0000 0x00 0x100000>;
			interrupts = <0x00 0xb0 0x04>;
			phandle = <0xd1>;
		};

		hevc-decoder@7eb00000 {
			compatible = "raspberrypi,rpivid-hevc-decoder";
			reg = <0x00 0x7eb00000 0x00 0x10000>;
			status = "okay";
		};

		rpivid-local-intc@7eb10000 {
			compatible = "raspberrypi,rpivid-local-intc";
			reg = <0x00 0x7eb10000 0x00 0x1000>;
			status = "okay";
			interrupts = <0x00 0x62 0x04>;
		};

		h264-decoder@7eb20000 {
			compatible = "raspberrypi,rpivid-h264-decoder";
			reg = <0x00 0x7eb20000 0x00 0x10000>;
			status = "okay";
		};

		vp9-decoder@7eb30000 {
			compatible = "raspberrypi,rpivid-vp9-decoder";
			reg = <0x00 0x7eb30000 0x00 0x10000>;
			status = "okay";
		};
	};

	leds {
		compatible = "gpio-leds";
		phandle = <0xd2>;

		act {
			label = "led0";
			default-state = "keep";
			linux,default-trigger = "mmc0";
			gpios = <0x0e 0x2a 0x00>;
			phandle = <0x38>;
		};

		pwr {
			label = "led1";
			gpios = <0x29 0x02 0x01>;
			linux,default-trigger = "default-on";
			phandle = <0x39>;
		};
	};

	__overrides__ {
		cam0-pwdn-ctrl;
		cam0-pwdn;
		cam0-led-ctrl;
		cam0-led;
		cache_line_size;
		uart0 = "\0\0\0*status";
		uart1 = "\0\0\0+status";
		i2s = "\0\0\0,status";
		spi = "\0\0\0-status";
		i2c0 = [00 00 00 0f 73 74 61 74 75 73 00 00 00 00 2e 73 74 61 74 75 73 00];
		i2c1 = "\0\0\0/status";
		i2c0_baudrate = [00 00 00 0f 63 6c 6f 63 6b 2d 66 72 65 71 75 65 6e 63 79 3a 30 00];
		i2c1_baudrate = "\0\0\0/clock-frequency:0";
		audio = "\0\0\0status";
		watchdog = [00 00 01 73 74 61 74 75 73 00];
		random = [00 00 02 73 74 61 74 75 73 00];
		axiperf = [00 00 06 73 74 61 74 75 73 00];
		arm_freq;
		act_led_gpio = "\0\0\08gpios:4";
		act_led_activelow = "\0\0\08gpios:8";
		act_led_trigger = "\0\0\08linux,default-trigger";
		pwr_led_gpio = "\0\0\09gpios:4";
		pwr_led_activelow = "\0\0\09gpios:8";
		pwr_led_trigger = "\0\0\09linux,default-trigger";
		eth_led0 = "\0\0\0(led-modes:0";
		eth_led1 = "\0\0\0(led-modes:4";
		spi_dma4 = <0x2d 0x646d6173 0x3a303d00 0x3a 0x2d 0x646d6173 0x3a383d00 0x3a>;
	};

	fixedregulator_3v3 {
		compatible = "regulator-fixed";
		regulator-always-on;
		regulator-max-microvolt = <0x325aa0>;
		regulator-min-microvolt = <0x325aa0>;
		regulator-name = "3v3";
		phandle = <0xd3>;
	};

	fixedregulator_5v0 {
		compatible = "regulator-fixed";
		regulator-always-on;
		regulator-max-microvolt = <0x4c4b40>;
		regulator-min-microvolt = <0x4c4b40>;
		regulator-name = "5v0";
		phandle = <0xd4>;
	};

	v3dbus {
		compatible = "simple-bus";
		#address-cells = <0x01>;
		#size-cells = <0x02>;
		ranges = <0x7c500000 0x00 0xfc500000 0x00 0x3300000 0x40000000 0x00 0xff800000 0x00 0x800000>;
		dma-ranges = <0x00 0x00 0x00 0x04 0x00>;
		phandle = <0xd5>;

		v3d@7ec04000 {
			compatible = "brcm,2711-v3d";
			reg = <0x7ec00000 0x00 0x4000 0x7ec04000 0x00 0x4000>;
			reg-names = "hub\0core0";
			power-domains = <0x31 0x01>;
			resets = <0x31 0x00>;
			clocks = <0x15 0x05>;
			clocks-names = "v3d";
			interrupts = <0x00 0x4a 0x04>;
			status = "disabled";
			phandle = <0xd6>;
		};
	};

	psci {
		compatible = "arm,psci-1.0";
		method = "smc";
		status = "okay";
	};

	interrupt-controller@fff841000 {
		interrupt-controller;
		#interrupt-cells = <0x03>;
		compatible = "arm,gic-400";
		reg = <0x0F 0xFF841000 0x00 0x1000 0x0F 0xFF842000 0x00 0x2000>;
		phandle = <0x01>;
	};

	memory@200000 {
    	device_type = "memory";
    	reg = <0x00 0x200000 0x00 0x3de00000>;
    };

    virtio_net@fa000800 {
        dma-coherent;
        compatible = "virtio,mmio";
        interrupts = <0x00 0x17 0x01>;
        reg = <0x00 0xfa000800 0x00 0x400>;
    };

    virtio_console@fa000c00 {
        dma-coherent;
        compatible = "virtio,mmio";
        interrupts = <0x00 0x20 0x01>;
        reg = <0x00 0xfa000c00 0x00 0x1000>;
    };

    virtio_console@fa002000 {
        dma-coherent;
        compatible = "virtio,mmio";
        interrupts = <0x00 0x21 0x01>;
        reg = <0x00 0xfa002000 0x00 0x1000>;
    };

    vm_service {
        compatible = "shyper";
        interrupts = <0x00 0x10 0x01>;
    };
};
